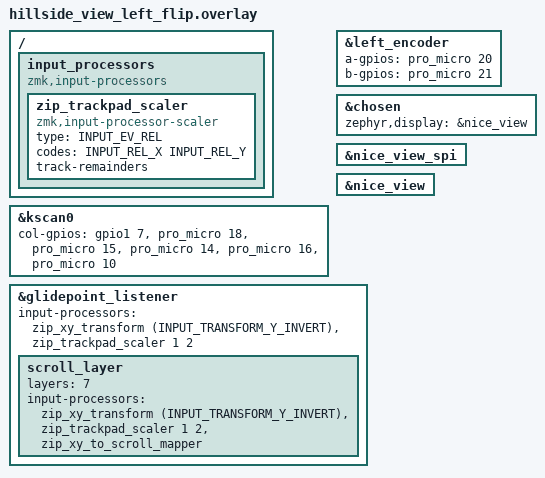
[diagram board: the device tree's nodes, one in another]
/*
 * Copyright (c) 2022 The ZMK Contributors
 *
 * SPDX-License-Identifier: MIT
 *
 * FLIPPED LAYOUT - LEFT/CENTRAL side
 * - Uses original LEFT PCB (flipped, MCU on top, sockets on opposite side)
 * - Display on central shows: layer, BT status, battery, WPM
 * - Receives Cirque input from right peripheral via BLE split
 * - Column GPIOs reversed to account for physical flip
 */

#include "hillside_view.dtsi"
#include <dt-bindings/zmk/input_transform.h>
#include <input/processors.dtsi>

&kscan0 {
    /* Same column order as original LEFT - flipping PCB doesn't change electrical routing */
    col-gpios
        = <&gpio1 7 GPIO_ACTIVE_HIGH>
        , <&pro_micro 18 GPIO_ACTIVE_HIGH>
        , <&pro_micro 15 GPIO_ACTIVE_HIGH>
        , <&pro_micro 14 GPIO_ACTIVE_HIGH>
        , <&pro_micro 16 GPIO_ACTIVE_HIGH>
        , <&pro_micro 10 GPIO_ACTIVE_HIGH>
        ;
};

&left_encoder {
    status = "okay";
    a-gpios = <&pro_micro 20 (GPIO_ACTIVE_HIGH | GPIO_PULL_UP)>;
    b-gpios = <&pro_micro 21 (GPIO_ACTIVE_HIGH | GPIO_PULL_UP)>;
};

&chosen {
    zephyr,display = &nice_view;
};

/* nice!view display */
&nice_view_spi {
    status = "okay";
};

&nice_view {
    status = "okay";
};

/* Trackpad sensitivity scaler - multiply movement by 2 */
/ {
    input_processors {
        compatible = "zmk,input-processors";
        zip_trackpad_scaler: zip_trackpad_scaler {
            compatible = "zmk,input-processor-scaler";
            #input-processor-cells = <2>;
            type = <INPUT_EV_REL>;
            codes = <INPUT_REL_X INPUT_REL_Y>;
            track-remainders;
        };
    };
};

/* Enable trackpad listener with Y-inversion (bare 40mm Cirque, no overlay) */
&glidepoint_listener {
    status = "okay";
    input-processors = <&zip_xy_transform (INPUT_TRANSFORM_Y_INVERT)>, <&zip_trackpad_scaler 1 2>;

    /* Layer override: convert trackpad to scroll on SCROLL layer (7) - slower scroll (1/2 speed) */
    scroll_layer {
        layers = <7>;
        input-processors = <&zip_xy_transform (INPUT_TRANSFORM_Y_INVERT)>, <&zip_trackpad_scaler 1 2>, <&zip_xy_to_scroll_mapper>;
    };
};
